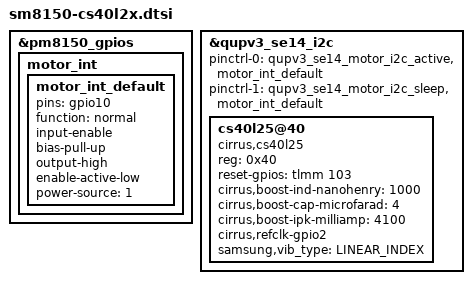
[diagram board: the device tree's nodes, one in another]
/* Copyright (c) 2016, The Linux Foundation. All rights reserved.
 *
 * This program is free software; you can redistribute it and/or modify
 * it under the terms of the GNU General Public License version 2 and
 * only version 2 as published by the Free Software Foundation.
 *
 * This program is distributed in the hope that it will be useful,
 * but WITHOUT ANY WARRANTY; without even the implied warranty of
 * MERCHANTABILITY or FITNESS FOR A PARTICULAR PURPOSE.  See the
 * GNU General Public License for more details.
 * 
 * 18.09.21 - fix dtsi for using tlmm with cs40l25 motor IC
 * 
 */

&pm8150_gpios {
	motor_int {
		motor_int_default: motor_int_default {
			pins = "gpio10";
			function = "normal";
			input-enable;
			bias-pull-up;
			output-high;
			enable-active-low;
			power-source = <1>;
		};
	};
};

&qupv3_se14_i2c {
	status = "okay";
	pinctrl-0 = <&qupv3_se14_motor_i2c_active &motor_int_default>;
	pinctrl-1 = <&qupv3_se14_motor_i2c_sleep &motor_int_default>;

	cs40l25@40 {
		status = "okay";
		compatible = "cirrus,cs40l25";
		reg = <0x40>;
		reset-gpios = <&tlmm 103 0>; // MOTOR_RST - GPIO 103
		cirrus,boost-ind-nanohenry = <1000>;
		cirrus,boost-cap-microfarad = <4>;
		cirrus,boost-ipk-milliamp = <4100>;
		cirrus,refclk-gpio2;
		samsung,vib_type = "LINEAR_INDEX";	// using cirrus motor IC and 1040 motor
	};
};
